# AT32F425 register map
Vendor: Keil; Series: AT32F425; File version: 1.0
CPU: CM4 r0p1, little endian, no MPU, FPU, 4 interrupt priority bits
Registers are 32-bit, read-write, reset 0x0 unless marked. A register's access mark holds for its fields unless they carry their own. Offsets are from the block's base; [hi:lo] are bit positions; {n}, {i} and the like mark numbered series; 'fields as' and 'values as' point back to an identical list.

## CRC — CRC calculation unit
Base 0x40023000
0x00 DT reset 0xFFFFFFFF — Data register
0x04 CDT — Common data register
  [7:0] CDT — Common Data
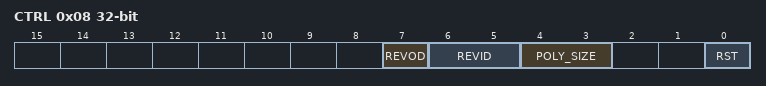
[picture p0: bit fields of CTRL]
0x08 CTRL — Control register
  [7] REVOD — Reverse output data
    0=NoEffect; 1=WordReverse
  [6:5] REVID — Reverse input data
    0=NoEffect; 1=ByteReverse; 2=HalfWordReverse; 3=WordReverse
  [4:3] POLY_SIZE — Polynomial size
    0=bits32 (32 bits); 1=bits16 (16 bits); 2=bits8 (8 bits); 3=bits7 (7 bits)
  [0] RST write-1-sets — Reset bit
    on write: 1=Reset CRC calculation unit, the data register is set as 0xFFFF FFFF
0x10 IDT reset 0xFFFFFFFF — Initial data register
0x14 POLY reset 0x4C11DB7 — Polynomial coefficient register

## NVIC — Nested Vectored Interrupt Controller
Base 0xE000E000
0x04 ICTR ro — Interrupt Controller Type Register
  [3:0] INTLINESNUM — Total number of interrupt lines in groups
0x100 ISER0 — Interrupt Set-Enable Register
  [31:0] SETENA
0x104 ISER1 — Interrupt Set-Enable Register
  [31:0] SETENA
0x180 ICER0 — Interrupt Clear-Enable Register
  [31:0] CLRENA
0x184 ICER1 — Interrupt Clear-Enable Register
  [31:0] CLRENA
0x200 ISPR0 — Interrupt Set-Pending Register
  [31:0] SETPEND
0x204 ISPR1 — Interrupt Set-Pending Register
  [31:0] SETPEND
0x280 ICPR0 — Interrupt Clear-Pending Register
  [31:0] CLRPEND
0x284 ICPR1 — Interrupt Clear-Pending Register
  [31:0] CLRPEND
0x300 IABR0 ro — Interrupt Active Bit Register
  [31:0] ACTIVE
0x304 IABR1 ro — Interrupt Active Bit Register
  [31:0] ACTIVE
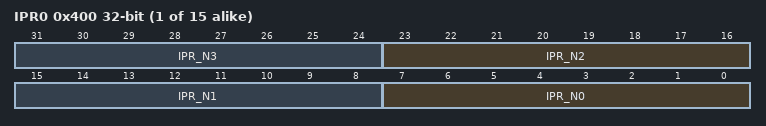
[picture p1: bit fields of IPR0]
{0x400+4i} IPR{i} (i=0..14) — Interrupt Priority Register
  [8n+7:8n] IPR_N{n} (n=0..3)
0xF00 STIR wo — Software Triggered Interrupt Register
  [8:0] INTID — interrupt to be triggered

## USB_OTG1_HOST — USB on the go full speed
Base 0x50000400
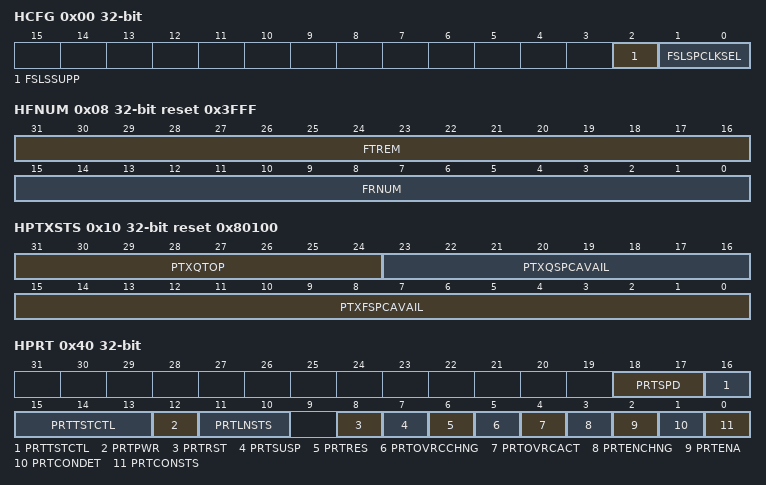
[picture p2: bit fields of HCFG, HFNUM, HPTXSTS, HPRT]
0x00 HCFG — OTGFS host configuration register (OTGFS_HCFG)
  [2] FSLSSUPP ro — FS- and LS-only support
  [1:0] FSLSPCLKSEL — FS/LS PHY clock select
0x04 HFIR reset 0xEA60 — OTGFS Host frame interval register
  [15:0] FRINT — Frame interval
0x08 HFNUM ro reset 0x3FFF — OTGFS host frame number/frame time remaining register (OTGFS_HFNUM)
  [31:16] FTREM — Frame time remaining
  [15:0] FRNUM — Frame number
0x10 HPTXSTS reset 0x80100 — OTGFS_Host periodic transmit FIFO/queue status register (OTGFS_HPTXSTS)
  [31:24] PTXQTOP ro — Top of the periodic transmit request queue
  [23:16] PTXQSPCAVAIL ro — Periodic transmit request queue space available
  [15:0] PTXFSPCAVAIL — Periodic transmit data FIFO space available
0x14 HAINT ro — OTGFS Host all channels interrupt register
  [15:0] HAINT — Channel interrupts
0x18 HAINTMSK — OTGFS host all channels interrupt mask register
  [15:0] HAINTMSK — Channel interrupt mask
0x40 HPRT — OTGFS host port control and status register (OTGFS_HPRT)
  [18:17] PRTSPD ro — Port speed
  [16:13] PRTTSTCTL — Port test control
  [12] PRTPWR — Port power
  [11:10] PRTLNSTS ro — Port line status
  [8] PRTRST — Port reset
  [7] PRTSUSP — Port suspend
  [6] PRTRES — Port resume
  [5] PRTOVRCCHNG — Port overcurrent change
  [4] PRTOVRCACT ro — Port overcurrent active
  [3] PRTENCHNG — Port enable/disable change
  [2] PRTENA — Port enable
  [1] PRTCONDET — Port connect detected
  [0] PRTCONSTS ro — Port connect status
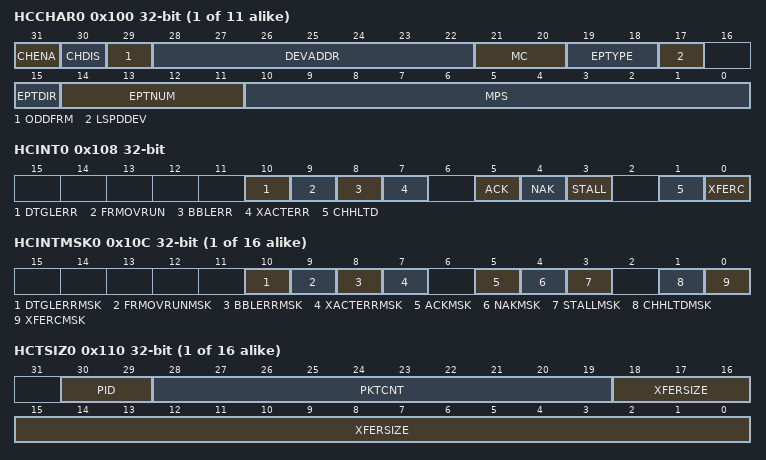
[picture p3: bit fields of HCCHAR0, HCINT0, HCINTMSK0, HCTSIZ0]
{0x100+0x20*i} HCCHAR{i} (i=0..10) — OTGFS host channel-{i} characteristics register (OTGFS_HCCHAR{i})
  [31] CHENA — Channel enable
  [30] CHDIS — Channel disable
  [29] ODDFRM — Odd frame
  [28:22] DEVADDR — Device address
  [21:20] MC — Multicount
  [19:18] EPTYPE — Endpoint type
  [17] LSPDDEV — Low-speed device
  [15] EPTDIR — Endpoint direction
  [14:11] EPTNUM — Endpoint number
  [10:0] MPS — Maximum packet size
0x108 HCINT0 — OTGFS host channel-0 interrupt register (OTGFS_HCINT0)
  [10] DTGLERR — Data toggle error
  [9] FRMOVRUN — Frame overrun
  [8] BBLERR — Babble error
  [7] XACTERR — Transaction error
  [5] ACK — ACK response received/transmitted interrupt
  [4] NAK — NAK response received interrupt
  [3] STALL — STALL response received interrupt
  [1] CHHLTD — Channel halted
  [0] XFERC — Transfer completed
{0x10C+0x20*i} HCINTMSK{i} (i=0..15) — OTGFS host channel-{i} mask register (OTGFS_HCINTMSK{i})
  [10] DTGLERRMSK — Data toggle error mask
  [9] FRMOVRUNMSK — Frame overrun mask
  [8] BBLERRMSK — Babble error mask
  [7] XACTERRMSK — Transaction error mask
  [5] ACKMSK — ACK response received/transmitted interrupt mask
  [4] NAKMSK — NAK response received interrupt mask
  [3] STALLMSK — STALL response received interrupt mask
  [1] CHHLTDMSK — Channel halted mask
  [0] XFERCMSK — Transfer completed mask
{0x110+0x20*i} HCTSIZ{i} (i=0..15) — OTGFS host channel-{i} transfer size register
  [30:29] PID
  [28:19] PKTCNT — Packet count
  [18:0] XFERSIZE — Transfer size
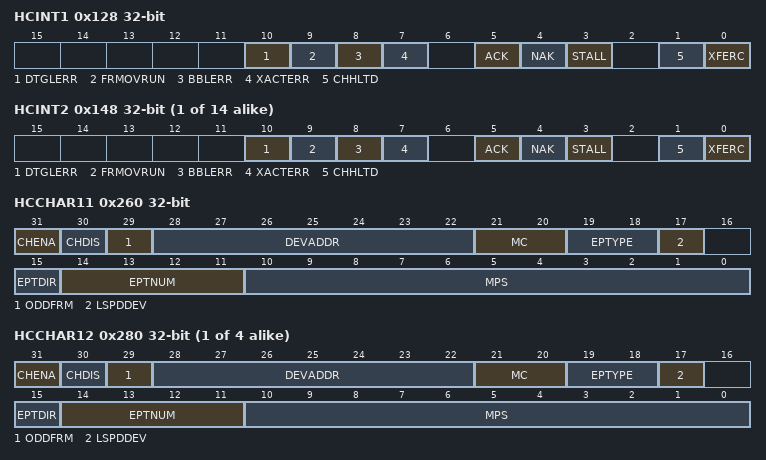
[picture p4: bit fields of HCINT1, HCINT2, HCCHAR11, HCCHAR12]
0x128 HCINT1 — OTG_FS host channel-1 interrupt register (OTG_FS_HCINT1)
  fields as HCINT0
{0x108+0x20*i} HCINT{i} (i=2..15) — OTGFS host channel-{i} interrupt register (OTGFS_HCINT{i})
  fields as HCINT0
0x260 HCCHAR11 — OTGFS host channel-7 characteristics register (OTGFS_HCCHAR11)
  fields as HCCHAR0
{0x100+0x20*i} HCCHAR{i} (i=12..15) — OTGFS host channel-{i} characteristics register (OTGFS_HCCHAR{i})
  fields as HCCHAR0

## USB_OTG1_PWRCLK — USB on the go full speed
Base 0x50000E00
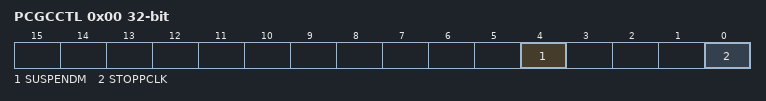
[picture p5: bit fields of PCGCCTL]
0x00 PCGCCTL — OTGFS power and clock gating control register (OTGFS_PCGCCTL)
  [4] SUSPENDM ro — PHY Suspended
  [0] STOPPCLK — Stop PHY clock
